# STM32H730 register map
File version: 1.8
CPU: CM7 r0p1, little endian, MPU, FPU, 4 interrupt priority bits
Registers are 32-bit, read-write, reset 0x0 unless marked. A register's access mark holds for its fields unless they carry their own. Offsets are from the block's base; [hi:lo] are bit positions; {n}, {i} and the like mark numbered series.

## DELAY_Block_SDMMC1
Base 0x52008000
Same registers: DELAY_Block_SDMMC2 0x48022800, Delay_Block_OCTOSPI1 0x52006000, Delay_Block_OCTOSPI2 0x5200B000
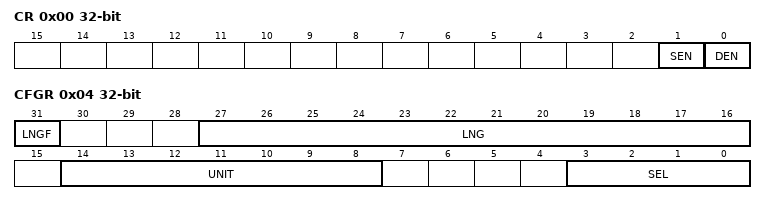
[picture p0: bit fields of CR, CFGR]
0x00 CR — DLYB control register
  [1] SEN — Sampler length enable bit
  [0] DEN — Delay block enable bit
0x04 CFGR — DLYB configuration register
  [31] LNGF — Length valid flag
  [27:16] LNG — Delay line length value
  [14:8] UNIT — Delay Defines the delay of a Unit delay cell
  [3:0] SEL — Select the phase for the Output clock

## Ethernet_MTL
Base 0x40028C00
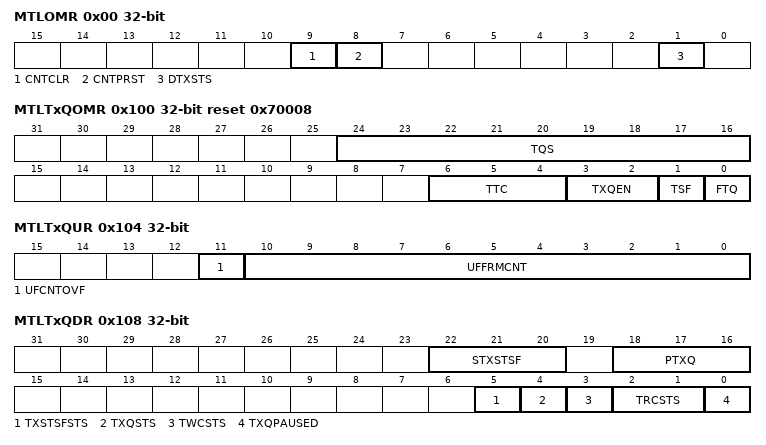
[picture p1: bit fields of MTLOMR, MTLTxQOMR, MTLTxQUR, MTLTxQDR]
0x00 MTLOMR access not given — Operating mode Register
  [9] CNTCLR — Counters Reset
  [8] CNTPRST — Counters Preset
  [1] DTXSTS — Drop Transmit Status
0x20 MTLISR access not given — Interrupt status Register
  [0] Q0IS — Queue interrupt status
0x100 MTLTxQOMR access not given reset 0x70008 — Tx queue operating mode Register
  [24:16] TQS — Transmit Queue Size
  [6:4] TTC — Transmit Threshold Control
  [3:2] TXQEN — Transmit Queue Enable
  [1] TSF — Transmit Store and Forward
  [0] FTQ — Flush Transmit Queue
0x104 MTLTxQUR access not given — Tx queue underflow register
  [11] UFCNTOVF — Overflow Bit for Underflow Packet Counter
  [10:0] UFFRMCNT — Underflow Packet Counter
0x108 MTLTxQDR access not given — Tx queue debug Register
  [22:20] STXSTSF — Number of Status Words in Tx Status FIFO of Queue
  [18:16] PTXQ — Number of Packets in the Transmit Queue
  [5] TXSTSFSTS — MTL Tx Status FIFO Full Status
  [4] TXQSTS — MTL Tx Queue Not Empty Status
  [3] TWCSTS — MTL Tx Queue Write Controller Status
  [2:1] TRCSTS — MTL Tx Queue Read Controller Status
  [0] TXQPAUSED — Transmit Queue in Pause
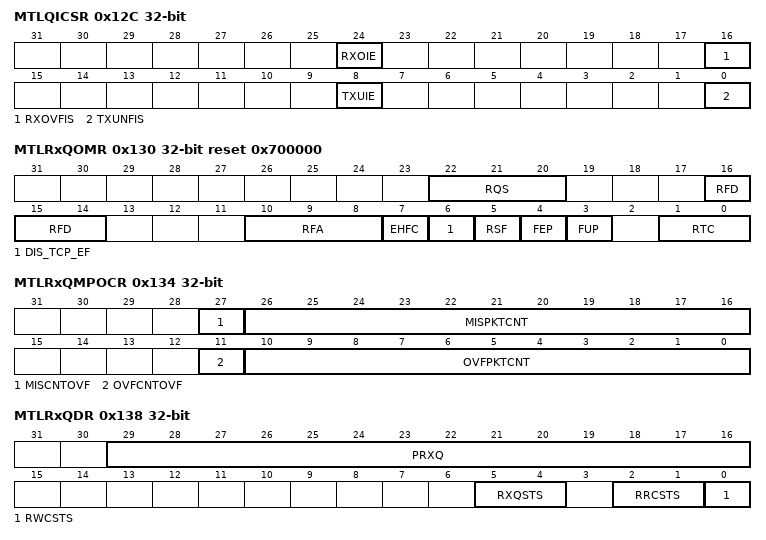
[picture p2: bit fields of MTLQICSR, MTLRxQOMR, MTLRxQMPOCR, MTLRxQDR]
0x12C MTLQICSR access not given — Queue interrupt control status Register
  [24] RXOIE — Receive Queue Overflow Interrupt Enable
  [16] RXOVFIS — Receive Queue Overflow Interrupt Status
  [8] TXUIE — Transmit Queue Underflow Interrupt Enable
  [0] TXUNFIS — Transmit Queue Underflow Interrupt Status
0x130 MTLRxQOMR access not given reset 0x700000 — Rx queue operating mode register
  [22:20] RQS — Receive Queue Size
  [16:14] RFD — Threshold for Deactivating Flow Control
  [10:8] RFA — Threshold for Activating Flow Control
  [7] EHFC — Enable Hardware Flow Control
  [6] DIS_TCP_EF — Disable Dropping of TCP
  [5] RSF — Receive Queue Store and Forward
  [4] FEP — Forward Error Packets
  [3] FUP — Forward Undersized Good Packets
  [1:0] RTC — Receive Queue Threshold Control
0x134 MTLRxQMPOCR access not given — Rx queue missed packet and overflow counter register
  [27] MISCNTOVF — Missed Packet Counter Overflow Bit
  [26:16] MISPKTCNT — Missed Packet Counter
  [11] OVFCNTOVF — Overflow Counter Overflow Bit
  [10:0] OVFPKTCNT — Overflow Packet Counter
0x138 MTLRxQDR access not given — Rx queue debug register
  [29:16] PRXQ — Number of Packets in Receive Queue
  [5:4] RXQSTS — MTL Rx Queue Fill-Level Status
  [2:1] RRCSTS — MTL Rx Queue Read Controller State
  [0] RWCSTS — MTL Rx Queue Write Controller Active Status

## HSEM
Base 0x58026400
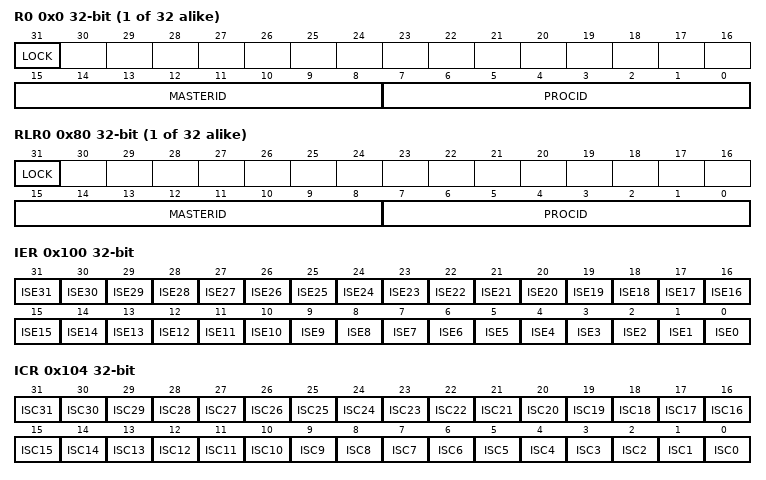
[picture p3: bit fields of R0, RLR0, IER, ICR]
{0x0+4i} R{i} (i=0..31) — HSEM register HSEM_R{i}
  [31] LOCK — Lock indication
    on read: 0=Free (Semaphore is free); 1=Locked (Semaphore is locked) | on write: 0=Free semaphore; 1=TryLock (Try to lock semaphore)
  [15:8] MASTERID range 0..15 — Semaphore MasterID
  [7:0] PROCID — Semaphore ProcessID
{0x80+4i} RLR{i} (i=0..31) ro — Semaphore {i} read lock register
  [31] LOCK — Lock indication
    0=Free (Semaphore is free); 1=Locked (Semaphore is locked)
  [15:8] MASTERID range 0..15 — Semaphore MasterID
  [7:0] PROCID — Semaphore ProcessID
0x100 IER — HSEM Interrupt enable register
  [n] ISE{n} (n=0..31) — Interrupt semaphore {n} enable bit
    0=Disabled (Interrupt generation disabled); 1=Enabled (Interrupt generation enabled)
0x104 ICR — HSEM Interrupt clear register
  [n] ISC{n} (n=0..31) — Interrupt semaphore {n} clear bit
    on read: 0=NoEffect (Always reads 0) | on write: 0=NoEffect (Interrupt semaphore x status ISFx and masked status MISFx not affected); 1=Clear (Interrupt semaphore x status ISFx and masked status MISFx cleared)
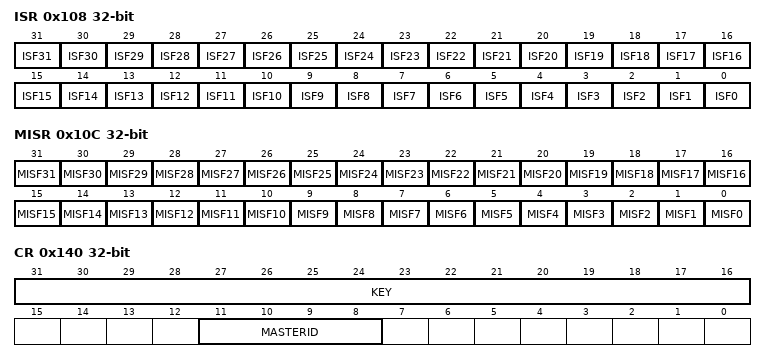
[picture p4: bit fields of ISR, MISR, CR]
0x108 ISR ro — HSEM Interrupt status register
  [n] ISF{n} (n=0..31) — Interrupt semaphore {n} status bit before enable (mask)
    0=NotPending (No interrupt pending); 1=Pending (Interrupt pending)
0x10C MISR ro — HSEM Masked interrupt status register
  [n] MISF{n} (n=0..31) — Masked interrupt semaphore {n} status bit after enable (mask)
    0=NotPending (No interrupt pending after masking); 1=Pending (Interrupt pending after masking)
0x140 CR — HSEM Clear register
  [31:16] KEY — Semaphore clear Key
  [11:8] MASTERID — MasterID of semaphores to be cleared
0x144 KEYR — HSEM Interrupt clear register
  [31:16] KEY — Semaphore Clear Key
